AUTOSAR XML (schema 4-2-2)
package /ComponentTypes
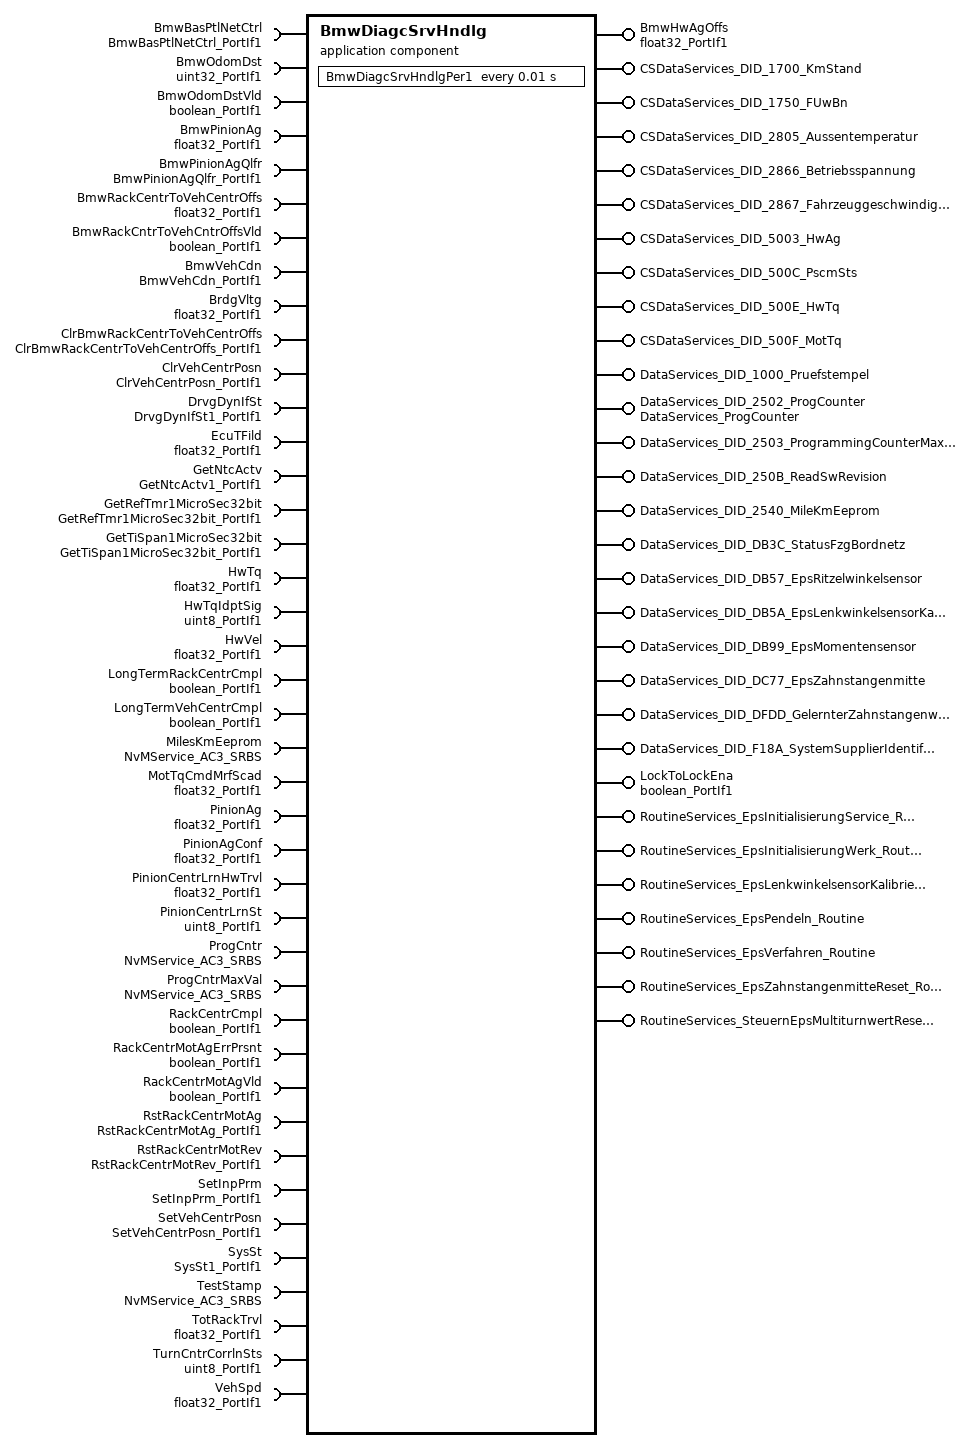
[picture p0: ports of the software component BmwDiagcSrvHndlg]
  application sw component type BmwDiagcSrvHndlg
    30 x provide port:
      BmwHwAgOffs: nonqueued-sender-com-spec{data-element=Val, init-value=0}, provided-interface=float32_PortIf1
      CSDataServices_DID_1700_KmStand: server-com-spec{operation=ReadData, queue-length=1}, provided-interface=CSDataServices_DID_1700_KmStand
      CSDataServices_DID_1750_FUwBn: server-com-spec{operation=ReadData, queue-length=1}, provided-interface=CSDataServices_DID_1750_FUwBn
      CSDataServices_DID_2805_Aussentemperatur: server-com-spec{operation=ReadData, queue-length=1}, provided-interface=CSDataServices_DID_2805_Aussentemperatur
      CSDataServices_DID_2866_Betriebsspannung: server-com-spec{operation=ReadData, queue-length=1}, provided-interface=CSDataServices_DID_2866_Betriebsspannung
      CSDataServices_DID_2867_Fahrzeuggeschwindigkeit: server-com-spec{operation=ReadData, queue-length=1}, provided-interface=CSDataServices_DID_2867_Fahrzeuggeschwindigkeit
      CSDataServices_DID_5003_HwAg: server-com-spec{operation=ReadData, queue-length=1}, provided-interface=CSDataServices_DID_5003_HwAg
      CSDataServices_DID_500C_PscmSts: server-com-spec{operation=ReadData, queue-length=1}, provided-interface=CSDataServices_DID_500C_PscmSts
      CSDataServices_DID_500E_HwTq: server-com-spec{operation=ReadData, queue-length=1}, provided-interface=CSDataServices_DID_500E_HwTq
      CSDataServices_DID_500F_MotTq: server-com-spec{operation=ReadData, queue-length=1}, provided-interface=CSDataServices_DID_500F_MotTq
      DataServices_DID_1000_Pruefstempel: provided-interface=DataServices_DID_1000_Pruefstempel
        provided-com-specs:
          operation=ConditionCheckRead, queue-length=1
          operation=ReadData, queue-length=1
          operation=WriteData, queue-length=1
      DataServices_DID_2502_ProgCounter: server-com-spec{operation=ReadData, queue-length=1}, provided-interface=DataServices_ProgCounter
      DataServices_DID_2503_ProgrammingCounterMaxValue: provided-interface=DataServices_DID_2503_ProgrammingCounterMaxValue
        provided-com-specs:
          operation=ConditionCheckRead, queue-length=1
          operation=ReadData, queue-length=1
          operation=WriteData, queue-length=1
      DataServices_DID_250B_ReadSwRevision: provided-com-specs=[{operation=ConditionCheckRead, queue-length=1}, {operation=ReadData, queue-length=1}], provided-interface=DataServices_DID_250B_ReadSwRevision
      DataServices_DID_2540_MileKmEeprom: provided-com-specs=[{operation=ConditionCheckRead, queue-length=1}, {operation=ReadData, queue-length=1}], provided-interface=DataServices_DID_2540_MileKmEeprom
      DataServices_DID_DB3C_StatusFzgBordnetz: provided-com-specs=[{operation=ConditionCheckRead, queue-length=1}, {operation=ReadData, queue-length=1}], provided-interface=DataServices_DID_DB3C_StatusFzgBordnetz
      DataServices_DID_DB57_EpsRitzelwinkelsensor: provided-com-specs=[{operation=ConditionCheckRead, queue-length=1}, {operation=ReadData, queue-length=1}], provided-interface=DataServices_DID_DB57_EpsRitzelwinkelsensor
      DataServices_DID_DB5A_EpsLenkwinkelsensorKalibrierung: provided-interface=DataServices_DID_DB5A_EpsLenkwinkelsensorKalibrierung
        provided-com-specs:
          operation=ConditionCheckRead, queue-length=1
          operation=ReadData, queue-length=1
          operation=WriteData, queue-length=1
      DataServices_DID_DB99_EpsMomentensensor: provided-com-specs=[{operation=ConditionCheckRead, queue-length=1}, {operation=ReadData, queue-length=1}], provided-interface=DataServices_DID_DB99_EpsMomentensensor
      DataServices_DID_DC77_EpsZahnstangenmitte: provided-com-specs=[{operation=ConditionCheckRead, queue-length=1}, {operation=ReadData, queue-length=1}], provided-interface=DataServices_DID_DC77_EpsZahnstangenmitte
      DataServices_DID_DFDD_GelernterZahnstangenweg: provided-com-specs=[{operation=ConditionCheckRead, queue-length=1}, {operation=ReadData, queue-length=1}], provided-interface=DataServices_DID_DFDD_GelernterZahnstangenweg
      DataServices_DID_F18A_SystemSupplierIdentifier: provided-com-specs=[{operation=ConditionCheckRead, queue-length=1}, {operation=ReadData, queue-length=1}], provided-interface=DataServices_DID_F18A_SystemSupplierIdentifier
      LockToLockEna: nonqueued-sender-com-spec{data-element=Logl, init-value=0}, provided-interface=boolean_PortIf1
      RoutineServices_EpsInitialisierungService_Routine: provided-interface=RoutineServices_EpsInitialisierungService_Routine
        provided-com-specs:
          operation=RequestResults, queue-length=1
          operation=Start, queue-length=1
          operation=Stop, queue-length=1
      RoutineServices_EpsInitialisierungWerk_Routine: provided-interface=RoutineServices_EpsInitialisierungWerk_Routine
        provided-com-specs:
          operation=RequestResults, queue-length=1
          operation=Start, queue-length=1
          operation=Stop, queue-length=1
      RoutineServices_EpsLenkwinkelsensorKalibrierungReset_Routine: server-com-spec{operation=Start, queue-length=1}, provided-interface=RoutineServices_EpsLenkwinkelsensorKalibrierungReset_Routine
      RoutineServices_EpsPendeln_Routine: provided-com-specs=[{operation=RequestResults, queue-length=1}, {operation=Start, queue-length=1}], provided-interface=RoutineServices_EpsPendeln_Routine
      RoutineServices_EpsVerfahren_Routine: provided-com-specs=[{operation=RequestResults, queue-length=1}, {operation=Start, queue-length=1}], provided-interface=RoutineServices_EpsVerfahren_Routine
      RoutineServices_EpsZahnstangenmitteReset_Routine: server-com-spec{operation=Start, queue-length=1}, provided-interface=RoutineServices_EpsZahnstangenmitteReset_Routine
      RoutineServices_SteuernEpsMultiturnwertReset_Routine: server-com-spec{operation=Start, queue-length=1}, provided-interface=RoutineServices_SteuernEpsMultiturnwertReset_Routine
    41 x require port:
      BmwBasPtlNetCtrl: nonqueued-receiver-com-spec{data-element=Val, filter=data-filter-type=ALWAYS, init-value=15}, required-interface=BmwBasPtlNetCtrl_PortIf1
      BmwOdomDst: nonqueued-receiver-com-spec{data-element=Val, filter=data-filter-type=ALWAYS, init-value=0}, required-interface=uint32_PortIf1
      BmwOdomDstVld: nonqueued-receiver-com-spec{data-element=Logl, filter=data-filter-type=ALWAYS, init-value=0}, required-interface=boolean_PortIf1
      BmwPinionAg: nonqueued-receiver-com-spec{data-element=Val, filter=data-filter-type=ALWAYS, init-value=0}, required-interface=float32_PortIf1
      BmwPinionAgQlfr: nonqueued-receiver-com-spec{data-element=Val, filter=data-filter-type=ALWAYS, init-value=14}, required-interface=BmwPinionAgQlfr_PortIf1
      BmwRackCentrToVehCentrOffs: nonqueued-receiver-com-spec{data-element=Val, filter=data-filter-type=ALWAYS, init-value=0}, required-interface=float32_PortIf1
      BmwRackCntrToVehCntrOffsVld: nonqueued-receiver-com-spec{data-element=Logl, filter=data-filter-type=ALWAYS, init-value=0}, required-interface=boolean_PortIf1
      BmwVehCdn: nonqueued-receiver-com-spec{data-element=Val, filter=data-filter-type=ALWAYS, init-value=15}, required-interface=BmwVehCdn_PortIf1
      BrdgVltg: nonqueued-receiver-com-spec{data-element=Val, filter=data-filter-type=ALWAYS, init-value=6}, required-interface=float32_PortIf1
      ClrBmwRackCentrToVehCentrOffs: client-com-spec=Oper, required-interface=ClrBmwRackCentrToVehCentrOffs_PortIf1
      ClrVehCentrPosn: client-com-spec=Oper, required-interface=ClrVehCentrPosn_PortIf1
      DrvgDynIfSt: nonqueued-receiver-com-spec{data-element=Val, filter=data-filter-type=ALWAYS, init-value=128}, required-interface=DrvgDynIfSt1_PortIf1
      EcuTFild: nonqueued-receiver-com-spec{data-element=Val, filter=data-filter-type=ALWAYS, init-value=25}, required-interface=float32_PortIf1
      GetNtcActv: client-com-spec=Oper, required-interface=GetNtcActv1_PortIf1
      GetRefTmr1MicroSec32bit: client-com-spec=Oper, required-interface=GetRefTmr1MicroSec32bit_PortIf1
      GetTiSpan1MicroSec32bit: client-com-spec=Oper, required-interface=GetTiSpan1MicroSec32bit_PortIf1
      HwTq: nonqueued-receiver-com-spec{data-element=Val, filter=data-filter-type=ALWAYS, init-value=0}, required-interface=float32_PortIf1
      HwTqIdptSig: nonqueued-receiver-com-spec{data-element=Val, filter=data-filter-type=ALWAYS, init-value=4}, required-interface=uint8_PortIf1
      HwVel: nonqueued-receiver-com-spec{data-element=Val, filter=data-filter-type=ALWAYS, init-value=0}, required-interface=float32_PortIf1
      LongTermRackCentrCmpl: nonqueued-receiver-com-spec{data-element=Logl, filter=data-filter-type=ALWAYS, init-value=0}, required-interface=boolean_PortIf1
      LongTermVehCentrCmpl: nonqueued-receiver-com-spec{data-element=Logl, filter=data-filter-type=ALWAYS, init-value=0}, required-interface=boolean_PortIf1
      MilesKmEeprom: required-com-specs=[EraseBlock, GetErrorStatus, InvalidateNvBlock, ReadBlock, SetRamBlockStatus, WriteBlock], required-interface=NvMService_AC3_SRBS
      MotTqCmdMrfScad: nonqueued-receiver-com-spec{data-element=Val, filter=data-filter-type=ALWAYS, init-value=0}, required-interface=float32_PortIf1
      PinionAg: nonqueued-receiver-com-spec{data-element=Val, filter=data-filter-type=ALWAYS, init-value=0}, required-interface=float32_PortIf1
      PinionAgConf: nonqueued-receiver-com-spec{data-element=Val, filter=data-filter-type=ALWAYS, init-value=0}, required-interface=float32_PortIf1
      PinionCentrLrnHwTrvl: nonqueued-receiver-com-spec{data-element=Val, filter=data-filter-type=ALWAYS, init-value=0}, required-interface=float32_PortIf1
      PinionCentrLrnSt: nonqueued-receiver-com-spec{data-element=Val, filter=data-filter-type=ALWAYS, init-value=0}, required-interface=uint8_PortIf1
      ProgCntr: required-com-specs=[EraseBlock, GetErrorStatus, InvalidateNvBlock, ReadBlock, SetRamBlockStatus, WriteBlock], required-interface=NvMService_AC3_SRBS
      ProgCntrMaxVal: required-com-specs=[EraseBlock, GetErrorStatus, InvalidateNvBlock, ReadBlock, SetRamBlockStatus, WriteBlock], required-interface=NvMService_AC3_SRBS
      RackCentrCmpl: nonqueued-receiver-com-spec{data-element=Logl, filter=data-filter-type=ALWAYS, init-value=0}, required-interface=boolean_PortIf1
      RackCentrMotAgErrPrsnt: nonqueued-receiver-com-spec{data-element=Logl, filter=data-filter-type=ALWAYS, init-value=0}, required-interface=boolean_PortIf1
      RackCentrMotAgVld: nonqueued-receiver-com-spec{data-element=Logl, filter=data-filter-type=ALWAYS, init-value=0}, required-interface=boolean_PortIf1
      RstRackCentrMotAg: client-com-spec=Oper, required-interface=RstRackCentrMotAg_PortIf1
      RstRackCentrMotRev: client-com-spec=Oper, required-interface=RstRackCentrMotRev_PortIf1
      SetInpPrm: client-com-spec=Oper, required-interface=SetInpPrm_PortIf1
      SetVehCentrPosn: client-com-spec=Oper, required-interface=SetVehCentrPosn_PortIf1
      SysSt: nonqueued-receiver-com-spec{data-element=Val, filter=data-filter-type=ALWAYS, init-value=3}, required-interface=SysSt1_PortIf1
      TestStamp: required-com-specs=[EraseBlock, GetErrorStatus, InvalidateNvBlock, ReadBlock, SetRamBlockStatus, WriteBlock], required-interface=NvMService_AC3_SRBS
      TotRackTrvl: nonqueued-receiver-com-spec{data-element=Val, filter=data-filter-type=ALWAYS, init-value=0}, required-interface=float32_PortIf1
      TurnCntrCorrlnSts: nonqueued-receiver-com-spec{data-element=Val, filter=data-filter-type=ALWAYS, init-value=3}, required-interface=uint8_PortIf1
      VehSpd: nonqueued-receiver-com-spec{data-element=Val, filter=data-filter-type=ALWAYS, init-value=0}, required-interface=float32_PortIf1
    behavior BmwDiagcSrvHndlg_InternalBehavior
      ar-typed-per-instance-memorys:
        20 x data, all with sw-calibration-access=READ-ONLY:
          ActvRid: type=uint16
          HandsONAbort: type=boolean
          HandsONAbortTi: type=uint32
          HandsONStrt: type=boolean
          HandsONStrtTi: type=uint32
          HwAgAbortTi: type=uint32
          HwAgOrHwVelChkRes: type=boolean
          HwVelAbortTi: type=uint32
          LockToLockRountineSts: type=uint8
          LrndPinionCentrHwTrvl: type=float32
          MilesKmEeprom: type=uint32
          OperStEnaWaitTi: type=uint32
          OperStPreStrtChk: type=boolean
          PrevCycleMilesKmEeprom: type=uint32
          ProgCntr: type=uint16
          ProgCntrMaxVal: type=uint16
          RoutineHwPosStrt: type=float32
          TarHwA: type=float32
          TarHwVel: type=float32
          TestStamp: type=Ary1D_u08_3
      46 x operation invoked event:
        OIT_BmwDiagcSrvFHndlgAmbT_Oper_CSDataServices_DID_2805_Aussentemperatur_ReadData: start-on-event=BmwDiagcSrvFHndlgAmbTRead_Oper, operation=CSDataServices_DID_2805_Aussentemperatur.ReadData
        OIT_BmwDiagcSrvFHndlgEpsBaseNwRead_Oper_CSDataServices_DID_1750_FUwBn_ReadData: start-on-event=BmwDiagcSrvFHndlgEpsBaseNwRead_Oper, operation=CSDataServices_DID_1750_FUwBn.ReadData
        OIT_BmwDiagcSrvFHndlgEpsBattVltgRead_Oper_CSDataServices_DID_2866_Betriebsspannung_ReadData: start-on-event=BmwDiagcSrvFHndlgEpsBattVltgRead_Oper, operation=CSDataServices_DID_2866_Betriebsspannung.ReadData
        OIT_BmwDiagcSrvFHndlgEpsFactryIninRes_Oper_RoutineServices_EpsInitialisierungWerk_Routine_RequestResults: start-on-event=BmwDiagcSrvFHndlgEpsFactryIninRes_Oper, operation=RoutineServices_EpsInitialisierungWerk_Routine.RequestResults
        OIT_BmwDiagcSrvFHndlgEpsFactryIninStop_Oper_RoutineServices_EpsInitialisierungWerk_Routine_Stop: start-on-event=BmwDiagcSrvFHndlgEpsFactryIninStop_Oper, operation=RoutineServices_EpsInitialisierungWerk_Routine.Stop
        OIT_BmwDiagcSrvFHndlgEpsFactryIninStrt_Oper_RoutineServices_EpsInitialisierungWerk_Routine_Start: start-on-event=BmwDiagcSrvFHndlgEpsFactryIninStrt_Oper, operation=RoutineServices_EpsInitialisierungWerk_Routine.Start
        OIT_BmwDiagcSrvFHndlgEpsPinionAgSnsrRead_Oper_DataServices_DID_DB57_EpsRitzelwinkelsensor_ReadData: start-on-event=BmwDiagcSrvFHndlgEpsPinionAgSnsrRead_Oper, operation=DataServices_DID_DB57_EpsRitzelwinkelsensor.ReadData
        OIT_BmwDiagcSrvFHndlgEpsPinionAgSnsrReadCdnChk_Oper_DataServices_DID_DB57_EpsRitzelwinkelsensor_ConditionCheckRead: start-on-event=BmwDiagcSrvFHndlgEpsPinionAgSnsrReadCdnChk_Oper, operation=DataServices_DID_DB57_EpsRitzelwinkelsensor.ConditionCheckRead
        OIT_BmwDiagcSrvFHndlgEpsProgCntrMaxValWrite_Oper_DataServices_DID_2503_ProgrammingCounterMaxValue_WriteData: start-on-event=BmwDiagcSrvFHndlgEpsProgCntrMaxValWrite_Oper, operation=DataServices_DID_2503_ProgrammingCounterMaxValue.WriteData
        OIT_BmwDiagcSrvFHndlgEpsSteerAgSnsrCalRead_Oper_DataServices_DID_DB5A_EpsLenkwinkelsensorKalibrierung_ReadData: start-on-event=BmwDiagcSrvFHndlgEpsSteerAgSnsrCalRead_Oper, operation=DataServices_DID_DB5A_EpsLenkwinkelsensorKalibrierung.ReadData
        OIT_BmwDiagcSrvFHndlgEpsSteerAgSnsrCalReadCdnChk_Oper_DataServices_DID_DB5A_EpsLenkwinkelsensorKalibrierung_ConditionCheckRead: start-on-event=BmwDiagcSrvFHndlgEpsSteerAgSnsrCalReadCdnChk_Oper, operation=DataServices_DID_DB5A_EpsLenkwinkelsensorKalibrierung.ConditionCheckRead
        OIT_BmwDiagcSrvFHndlgEpsSteerAgSnsrCalWrite_Oper_DataServices_DID_DB5A_EpsLenkwinkelsensorKalibrierung_WriteData: start-on-event=BmwDiagcSrvFHndlgEpsSteerAgSnsrCalWrite_Oper, operation=DataServices_DID_DB5A_EpsLenkwinkelsensorKalibrierung.WriteData
        OIT_BmwDiagcSrvFHndlgEpsTestStampRead_Oper_DataServices_DID_1000_Pruefstempel_ReadData: start-on-event=BmwDiagcSrvFHndlgEpsTestStampRead_Oper, operation=DataServices_DID_1000_Pruefstempel.ReadData
        OIT_BmwDiagcSrvFHndlgEpsTestStampReadCdnChk_Oper_DataServices_DID_1000_Pruefstempel_ConditionCheckRead: start-on-event=BmwDiagcSrvFHndlgEpsTestStampReadCdnChk_Oper, operation=DataServices_DID_1000_Pruefstempel.ConditionCheckRead
        OIT_BmwDiagcSrvFHndlgEpsTestStampWrite_Oper_DataServices_DID_1000_Pruefstempel_WriteData: start-on-event=BmwDiagcSrvFHndlgEpsTestStampWrite_Oper, operation=DataServices_DID_1000_Pruefstempel.WriteData
        OIT_BmwDiagcSrvFHndlgHwAgRead_Oper_CSDataServices_DID_5003_HwAg_ReadData: start-on-event=BmwDiagcSrvFHndlgHwAgRead_Oper, operation=CSDataServices_DID_5003_HwAg.ReadData
        OIT_BmwDiagcSrvFHndlgHwTqRead_Oper_CSDataServices_DID_500E_HwTq_ReadData: start-on-event=BmwDiagcSrvFHndlgHwTqRead_Oper, operation=CSDataServices_DID_500E_HwTq.ReadData
        OIT_BmwDiagcSrvFHndlgMileKmEepromRead_Oper_DataServices_DID_2540_MileKmEeprom_ReadData: start-on-event=BmwDiagcSrvFHndlgMileKmEepromRead_Oper, operation=DataServices_DID_2540_MileKmEeprom.ReadData
        OIT_BmwDiagcSrvFHndlgMileKmEepromReadCdnChk_Oper_DataServices_DID_2540_MileKmEeprom_ConditionCheckRead: start-on-event=BmwDiagcSrvFHndlgMileKmEepromReadCdnChk_Oper, operation=DataServices_DID_2540_MileKmEeprom.ConditionCheckRead
        OIT_BmwDiagcSrvFHndlgMotTqRead_Oper_CSDataServices_DID_500F_MotTq_ReadData: start-on-event=BmwDiagcSrvFHndlgMotTqRead_Oper, operation=CSDataServices_DID_500F_MotTq.ReadData
        OIT_BmwDiagcSrvFHndlgProgmCntrMaxValRead_Oper_DataServices_DID_2503_ProgrammingCounterMaxValue_ReadData: start-on-event=BmwDiagcSrvFHndlgProgmCntrMaxValRead_Oper, operation=DataServices_DID_2503_ProgrammingCounterMaxValue.ReadData
        OIT_BmwDiagcSrvFHndlgProgmCntrMaxValReadCdnChk_Oper_DataServices_DID_2503_ProgrammingCounterMaxValue_ConditionCheckRead: start-on-event=BmwDiagcSrvFHndlgProgmCntrMaxValReadCdnChk_Oper, operation=DataServices_DID_2503_ProgrammingCounterMaxValue.ConditionCheckRead
        OIT_BmwDiagcSrvFHndlgProgmCntrRead_Oper_DataServices_DID_2502_ProgCounter_ReadData: start-on-event=BmwDiagcSrvFHndlgProgmCntrRead_Oper, operation=DataServices_DID_2502_ProgCounter.ReadData
        OIT_BmwDiagcSrvFHndlgPscmStsRead_Oper_CSDataServices_DID_500C_PscmSts_ReadData: start-on-event=BmwDiagcSrvFHndlgPscmStsRead_Oper, operation=CSDataServices_DID_500C_PscmSts.ReadData
        OIT_BmwDiagcSrvFHndlgReadSwRevision_Oper_DataServices_DID_250B_ReadSwRevision_ReadData: start-on-event=BmwDiagcSrvFHndlgReadSwRevision_Oper, operation=DataServices_DID_250B_ReadSwRevision.ReadData
        OIT_BmwDiagcSrvFHndlgReadSwRevisionCdnChk_Oper_DataServices_DID_250B_ReadSwRevision_ConditionCheckRead: start-on-event=BmwDiagcSrvFHndlgReadSwRevisionCdnChk_Oper, operation=DataServices_DID_250B_ReadSwRevision.ConditionCheckRead
        OIT_BmwDiagcSrvFHndlgStordRackTrvlAndCentrDataRead_Oper_DataServices_DID_DFDD_GelernterZahnstangenweg_ReadData: start-on-event=BmwDiagcSrvFHndlgStordRackTrvlAndCentrDataRead_Oper, operation=DataServices_DID_DFDD_GelernterZahnstangenweg.ReadData
        OIT_BmwDiagcSrvFHndlgStordRackTrvlAndCentrDataReadCdnChk_Oper_DataServices_DID_DFDD_GelernterZahnstangenweg_ConditionCheckRead: start-on-event=BmwDiagcSrvFHndlgStordRackTrvlAndCentrDataReadCdnChk_Oper, operation=DataServices_DID_DFDD_GelernterZahnstangenweg.ConditionCheckRead
        OIT_BmwDiagcSrvFHndlgSysSupplierIdentifieCdnChk_Oper_DataServices_DID_F18A_SystemSupplierIdentifier_ConditionCheckRead: start-on-event=BmwDiagcSrvFHndlgSysSupplierIdentifierCdnChk_Oper, operation=DataServices_DID_F18A_SystemSupplierIdentifier.ConditionCheckRead
        OIT_BmwDiagcSrvFHndlgSysSupplierIdentifierRead_Oper_DataServices_DID_F18A_SystemSupplierIdentifier_ReadData: start-on-event=BmwDiagcSrvFHndlgSysSupplierIdentifierRead_Oper, operation=DataServices_DID_F18A_SystemSupplierIdentifier.ReadData
        OIT_BmwDiagcSrvFHndlgVehSpdRead_Oper_CSDataServices_DID_2867_Fahrzeuggeschwindigkeit_ReadData: start-on-event=BmwDiagcSrvFHndlgVehSpdRead_Oper, operation=CSDataServices_DID_2867_Fahrzeuggeschwindigkeit.ReadData
        OIT_BmwDiagcSrvFHndlMileageRead_Oper_CSDataServices_DID_1700_KmStand_ReadData: start-on-event=BmwDiagcSrvFHndlMileageRead_Oper, operation=CSDataServices_DID_1700_KmStand.ReadData
        OIT_BmwDiagcSrvHndlgEpsCommuteRes_Oper_RoutineServices_EpsPendeln_Routine_RequestResults: start-on-event=BmwDiagcSrvHndlgEpsCommuteRes_Oper, operation=RoutineServices_EpsPendeln_Routine.RequestResults
        OIT_BmwDiagcSrvHndlgEpsCommuteStrt_Oper_RoutineServices_EpsPendeln_Routine_Start: start-on-event=BmwDiagcSrvHndlgEpsCommuteStrt_Oper, operation=RoutineServices_EpsPendeln_Routine.Start
        OIT_BmwDiagcSrvHndlgEpsIninSrvRes_Oper_RoutineServices_EpsInitialisierungService_Routine_RequestResults: start-on-event=BmwDiagcSrvHndlgEpsIninSrvRes_Oper, operation=RoutineServices_EpsInitialisierungService_Routine.RequestResults
        OIT_BmwDiagcSrvHndlgEpsIninSrvStop_Oper_RoutineServices_EpsInitialisierungService_Routine_Stop: start-on-event=BmwDiagcSrvHndlgEpsIninSrvStop_Oper, operation=RoutineServices_EpsInitialisierungService_Routine.Stop
        OIT_BmwDiagcSrvHndlgEpsIninSrvStrt_Oper_RoutineServices_EpsInitialisierungService_Routine_Start: start-on-event=BmwDiagcSrvHndlgEpsIninSrvStrt_Oper, operation=RoutineServices_EpsInitialisierungService_Routine.Start
        OIT_BmwDiagcSrvHndlgEpsProcRes_Oper_RoutineServices_EpsVerfahren_Routine_RequestResults: start-on-event=BmwDiagcSrvHndlgEpsProcRes_Oper, operation=RoutineServices_EpsVerfahren_Routine.RequestResults
        OIT_BmwDiagcSrvHndlgEpsProcStrt_Oper_RoutineServices_EpsVerfahren_Routine_Start: start-on-event=BmwDiagcSrvHndlgEpsProcStrt_Oper, operation=RoutineServices_EpsVerfahren_Routine.Start
        OIT_BmwDiagcSrvHndlgEpsPtlRackCentrRstStrt_Oper_RoutineServices_SteuernEpsMultiturnwertReset_Routine_Start: start-on-event=BmwDiagcSrvHndlgEpsPtlRackCentrRstStrt_Oper, operation=RoutineServices_SteuernEpsMultiturnwertReset_Routine.Start
        OIT_BmwDiagcSrvHndlgEpsRackCentrMotAgStsRead_Oper_DataServices_DID_DC77_EpsZahnstangenmitte_ReadData: start-on-event=BmwDiagcSrvHndlgEpsRackCentrMotAgStsRead_Oper, operation=DataServices_DID_DC77_EpsZahnstangenmitte.ReadData
        OIT_BmwDiagcSrvHndlgEpsRackCentrMotAgStsReadCdnChk_Oper_DataServices_DID_DC77_EpsZahnstangenmitte_ConditionCheckRead: start-on-event=BmwDiagcSrvHndlgEpsRackCentrMotAgStsReadCdnChk_Oper, operation=DataServices_DID_DC77_EpsZahnstangenmitte.ConditionCheckRead
        OIT_BmwDiagcSrvHndlgEpsRackCentrRstStrt_Oper_RoutineServices_EpsZahnstangenmitteReset_Routine_Start: start-on-event=BmwDiagcSrvHndlgEpsRackCentrRstStrt_Oper, operation=RoutineServices_EpsZahnstangenmitteReset_Routine.Start
        OIT_BmwDiagcSrvHndlgEpsSteerAgSnsrCalRstStrt_Oper_RoutineServices_EpsLenkwinkelsensorKalibrierungReset_Routine_Start: start-on-event=BmwDiagcSrvHndlgEpsSteerAgSnsrCalRstStrt_Oper, operation=RoutineServices_EpsLenkwinkelsensorKalibrierungReset_Routine.Start
        OIT_BmwDiagcSrvHndlgEpsTqSensrRead_Oper_DataServices_DID_DB99_EpsMomentensensor_ReadData: start-on-event=BmwDiagcSrvHndlgEpsTqSensrRead_Oper, operation=DataServices_DID_DB99_EpsMomentensensor.ReadData
        OIT_BmwDiagcSrvHndlgEpsTqSensrReadCdnChk_Oper_DataServices_DID_DB99_EpsMomentensensor_ConditionCheckRead: start-on-event=BmwDiagcSrvHndlgEpsTqSensrReadCdnChk_Oper, operation=DataServices_DID_DB99_EpsMomentensensor.ConditionCheckRead
      init event BmwDiagcSrvHndlig_InitEvent: start-on-event=BmwDiagcSrvHndlgInit1
      timing event TMT_BmwDiagcSrvHndlgPer1: start-on-event=BmwDiagcSrvHndlgPer1, period=0.01
      operation invoked event OIT_BmwDiagcSrvHndlgStatusFzgBordnetzRead_Oper_DataServices_DID_DB3C_StatusFzgBordnetz_ReadData: start-on-event=BmwDiagcSrvHndlgStatusFzgBordnetzRead_Oper, operation=DataServices_DID_DB3C_StatusFzgBordnetz.ReadData
      operation invoked event OIT_BmwDiagcSrvHndlgStatusFzgBordnetzReadCdnChk_Oper_DataServices_DID_DB3C_StatusFzgBordnetz_ConditionCheckRead: start-on-event=BmwDiagcSrvHndlgStatusFzgBordnetzReadCdnChk_Oper, operation=DataServices_DID_DB3C_StatusFzgBordnetz.ConditionCheckRead
      per-instance-parameters:
        parameter data prototype ProgCntrMaxValDft: sw-calibration-access=READ-WRITE, type=uint16, init-value=1000
      port-api-options:
        enable-take-address=false, error-handling=NO-TRANSFORMER-ERROR-HANDLING, indirect-api=false, port=BmwBasPtlNetCtrl
        enable-take-address=false, error-handling=NO-TRANSFORMER-ERROR-HANDLING, indirect-api=false, port=BmwHwAgOffs
        enable-take-address=false, error-handling=NO-TRANSFORMER-ERROR-HANDLING, indirect-api=false, port=BmwOdomDst
        enable-take-address=false, error-handling=NO-TRANSFORMER-ERROR-HANDLING, indirect-api=false, port=BmwOdomDstVld
        enable-take-address=false, error-handling=NO-TRANSFORMER-ERROR-HANDLING, indirect-api=false, port=BmwPinionAg
        enable-take-address=false, error-handling=NO-TRANSFORMER-ERROR-HANDLING, indirect-api=false, port=BmwPinionAgQlfr
        enable-take-address=false, error-handling=NO-TRANSFORMER-ERROR-HANDLING, indirect-api=false, port=BmwRackCentrToVehCentrOffs
        enable-take-address=false, error-handling=NO-TRANSFORMER-ERROR-HANDLING, indirect-api=false, port=BmwRackCntrToVehCntrOffsVld
        enable-take-address=false, error-handling=NO-TRANSFORMER-ERROR-HANDLING, indirect-api=false, port=BmwVehCdn
        enable-take-address=false, error-handling=NO-TRANSFORMER-ERROR-HANDLING, indirect-api=false, port=BrdgVltg
        enable-take-address=false, error-handling=NO-TRANSFORMER-ERROR-HANDLING, indirect-api=false, port=ClrBmwRackCentrToVehCentrOffs
        enable-take-address=false, error-handling=NO-TRANSFORMER-ERROR-HANDLING, indirect-api=false, port=ClrVehCentrPosn
        enable-take-address=false, error-handling=NO-TRANSFORMER-ERROR-HANDLING, indirect-api=false, port=CSDataServices_DID_1700_KmStand
        enable-take-address=false, error-handling=NO-TRANSFORMER-ERROR-HANDLING, indirect-api=false, port=CSDataServices_DID_1750_FUwBn
        enable-take-address=false, error-handling=NO-TRANSFORMER-ERROR-HANDLING, indirect-api=false, port=CSDataServices_DID_2805_Aussentemperatur
        enable-take-address=false, error-handling=NO-TRANSFORMER-ERROR-HANDLING, indirect-api=false, port=CSDataServices_DID_2866_Betriebsspannung
        enable-take-address=false, error-handling=NO-TRANSFORMER-ERROR-HANDLING, indirect-api=false, port=CSDataServices_DID_2867_Fahrzeuggeschwindigkeit
        enable-take-address=false, error-handling=NO-TRANSFORMER-ERROR-HANDLING, indirect-api=false, port=CSDataServices_DID_5003_HwAg
        enable-take-address=false, error-handling=NO-TRANSFORMER-ERROR-HANDLING, indirect-api=false, port=CSDataServices_DID_500C_PscmSts
        enable-take-address=false, error-handling=NO-TRANSFORMER-ERROR-HANDLING, indirect-api=false, port=CSDataServices_DID_500E_HwTq
        enable-take-address=false, error-handling=NO-TRANSFORMER-ERROR-HANDLING, indirect-api=false, port=CSDataServices_DID_500F_MotTq
        enable-take-address=false, error-handling=NO-TRANSFORMER-ERROR-HANDLING, indirect-api=false, port=DataServices_DID_1000_Pruefstempel
        enable-take-address=false, error-handling=NO-TRANSFORMER-ERROR-HANDLING, indirect-api=false, port=DataServices_DID_2502_ProgCounter
        enable-take-address=false, error-handling=NO-TRANSFORMER-ERROR-HANDLING, indirect-api=false, port=DataServices_DID_2503_ProgrammingCounterMaxValue
        enable-take-address=false, error-handling=NO-TRANSFORMER-ERROR-HANDLING, indirect-api=false, port=DataServices_DID_250B_ReadSwRevision
        enable-take-address=false, error-handling=NO-TRANSFORMER-ERROR-HANDLING, indirect-api=false, port=DataServices_DID_2540_MileKmEeprom
        enable-take-address=false, error-handling=NO-TRANSFORMER-ERROR-HANDLING, indirect-api=false, port=DataServices_DID_DB3C_StatusFzgBordnetz
        enable-take-address=false, error-handling=NO-TRANSFORMER-ERROR-HANDLING, indirect-api=false, port=DataServices_DID_DB57_EpsRitzelwinkelsensor
        enable-take-address=false, error-handling=NO-TRANSFORMER-ERROR-HANDLING, indirect-api=false, port=DataServices_DID_DB5A_EpsLenkwinkelsensorKalibrierung
        enable-take-address=false, error-handling=NO-TRANSFORMER-ERROR-HANDLING, indirect-api=false, port=DataServices_DID_DB99_EpsMomentensensor
        enable-take-address=false, error-handling=NO-TRANSFORMER-ERROR-HANDLING, indirect-api=false, port=DataServices_DID_DC77_EpsZahnstangenmitte
        enable-take-address=false, error-handling=NO-TRANSFORMER-ERROR-HANDLING, indirect-api=false, port=DataServices_DID_DFDD_GelernterZahnstangenweg
        enable-take-address=false, error-handling=NO-TRANSFORMER-ERROR-HANDLING, indirect-api=false, port=DataServices_DID_F18A_SystemSupplierIdentifier
        enable-take-address=false, error-handling=NO-TRANSFORMER-ERROR-HANDLING, indirect-api=false, port=DrvgDynIfSt
        enable-take-address=false, error-handling=NO-TRANSFORMER-ERROR-HANDLING, indirect-api=false, port=EcuTFild
        enable-take-address=false, error-handling=NO-TRANSFORMER-ERROR-HANDLING, indirect-api=false, port=GetNtcActv
        enable-take-address=false, error-handling=NO-TRANSFORMER-ERROR-HANDLING, indirect-api=false, port=GetRefTmr1MicroSec32bit
        enable-take-address=false, error-handling=NO-TRANSFORMER-ERROR-HANDLING, indirect-api=false, port=GetTiSpan1MicroSec32bit
        enable-take-address=false, error-handling=NO-TRANSFORMER-ERROR-HANDLING, indirect-api=false, port=HwTq
        enable-take-address=false, error-handling=NO-TRANSFORMER-ERROR-HANDLING, indirect-api=false, port=HwTqIdptSig
        enable-take-address=false, error-handling=NO-TRANSFORMER-ERROR-HANDLING, indirect-api=false, port=HwVel
        enable-take-address=false, error-handling=NO-TRANSFORMER-ERROR-HANDLING, indirect-api=false, port=LockToLockEna
        enable-take-address=false, error-handling=NO-TRANSFORMER-ERROR-HANDLING, indirect-api=false, port=LongTermRackCentrCmpl
        enable-take-address=false, error-handling=NO-TRANSFORMER-ERROR-HANDLING, indirect-api=false, port=LongTermVehCentrCmpl
        enable-take-address=false, error-handling=NO-TRANSFORMER-ERROR-HANDLING, indirect-api=false, port=MilesKmEeprom
        enable-take-address=false, error-handling=NO-TRANSFORMER-ERROR-HANDLING, indirect-api=false, port=MotTqCmdMrfScad
        enable-take-address=false, error-handling=NO-TRANSFORMER-ERROR-HANDLING, indirect-api=false, port=PinionAg
        enable-take-address=false, error-handling=NO-TRANSFORMER-ERROR-HANDLING, indirect-api=false, port=PinionAgConf
        enable-take-address=false, error-handling=NO-TRANSFORMER-ERROR-HANDLING, indirect-api=false, port=PinionCentrLrnHwTrvl
        enable-take-address=false, error-handling=NO-TRANSFORMER-ERROR-HANDLING, indirect-api=false, port=PinionCentrLrnSt
        enable-take-address=false, error-handling=NO-TRANSFORMER-ERROR-HANDLING, indirect-api=false, port=ProgCntr
        enable-take-address=false, error-handling=NO-TRANSFORMER-ERROR-HANDLING, indirect-api=false, port=ProgCntrMaxVal
        enable-take-address=false, error-handling=NO-TRANSFORMER-ERROR-HANDLING, indirect-api=false, port=RackCentrCmpl
        enable-take-address=false, error-handling=NO-TRANSFORMER-ERROR-HANDLING, indirect-api=false, port=RackCentrMotAgErrPrsnt
        enable-take-address=false, error-handling=NO-TRANSFORMER-ERROR-HANDLING, indirect-api=false, port=RackCentrMotAgVld
        enable-take-address=false, error-handling=NO-TRANSFORMER-ERROR-HANDLING, indirect-api=false, port=RoutineServices_EpsInitialisierungService_Routine
        enable-take-address=false, error-handling=NO-TRANSFORMER-ERROR-HANDLING, indirect-api=false, port=RoutineServices_EpsInitialisierungWerk_Routine
        enable-take-address=false, error-handling=NO-TRANSFORMER-ERROR-HANDLING, indirect-api=false, port=RoutineServices_EpsLenkwinkelsensorKalibrierungReset_Routine
        enable-take-address=false, error-handling=NO-TRANSFORMER-ERROR-HANDLING, indirect-api=false, port=RoutineServices_EpsPendeln_Routine
        enable-take-address=false, error-handling=NO-TRANSFORMER-ERROR-HANDLING, indirect-api=false, port=RoutineServices_EpsVerfahren_Routine
        enable-take-address=false, error-handling=NO-TRANSFORMER-ERROR-HANDLING, indirect-api=false, port=RoutineServices_EpsZahnstangenmitteReset_Routine
        enable-take-address=false, error-handling=NO-TRANSFORMER-ERROR-HANDLING, indirect-api=false, port=RoutineServices_SteuernEpsMultiturnwertReset_Routine
        enable-take-address=false, error-handling=NO-TRANSFORMER-ERROR-HANDLING, indirect-api=false, port=RstRackCentrMotAg
        enable-take-address=false, error-handling=NO-TRANSFORMER-ERROR-HANDLING, indirect-api=false, port=RstRackCentrMotRev
        enable-take-address=false, error-handling=NO-TRANSFORMER-ERROR-HANDLING, indirect-api=false, port=SetInpPrm
        enable-take-address=false, error-handling=NO-TRANSFORMER-ERROR-HANDLING, indirect-api=false, port=SetVehCentrPosn
        enable-take-address=false, error-handling=NO-TRANSFORMER-ERROR-HANDLING, indirect-api=false, port=SysSt
        enable-take-address=false, error-handling=NO-TRANSFORMER-ERROR-HANDLING, indirect-api=false, port=TestStamp
        enable-take-address=false, error-handling=NO-TRANSFORMER-ERROR-HANDLING, indirect-api=false, port=TotRackTrvl
        enable-take-address=false, error-handling=NO-TRANSFORMER-ERROR-HANDLING, indirect-api=false, port=TurnCntrCorrlnSts
        enable-take-address=false, error-handling=NO-TRANSFORMER-ERROR-HANDLING, indirect-api=false, port=VehSpd
      50 x runnable:
        BmwDiagcSrvFHndlgAmbTRead_Oper
          data-receive-point-by-arguments:
            access REC_EcuTFild_Val: accessed-variable=EcuTFild.Val
        BmwDiagcSrvFHndlgEpsBaseNwRead_Oper
          data-receive-point-by-arguments:
            access REC_BmwBasPtlNetCtrl_Val: accessed-variable=BmwBasPtlNetCtrl.Val
            access REC_BmwVehCdn_Val: accessed-variable=BmwVehCdn.Val
        BmwDiagcSrvFHndlgEpsBattVltgRead_Oper
          data-receive-point-by-arguments:
            access REC_BrdgVltg_Val: accessed-variable=BrdgVltg.Val
        BmwDiagcSrvFHndlgEpsFactryIninRes_Oper
        BmwDiagcSrvFHndlgEpsFactryIninStop_Oper
          data-send-points:
            access SEND_LockToLockEna_Logl: accessed-variable=LockToLockEna.Logl
        BmwDiagcSrvFHndlgEpsFactryIninStrt_Oper
          data-receive-point-by-arguments:
            6 x access:
              REC_HwTq_Val: accessed-variable=HwTq.Val
              REC_HwVel_Val: accessed-variable=HwVel.Val
              REC_LongTermRackCentrCmpl_Logl: accessed-variable=LongTermRackCentrCmpl.Logl
              REC_PinionAgConf_Val: accessed-variable=PinionAgConf.Val
              REC_SysSt_Val: accessed-variable=SysSt.Val
              REC_VehSpd_Val: accessed-variable=VehSpd.Val
          data-send-points:
            access SEND_LockToLockEna_Logl: accessed-variable=LockToLockEna.Logl
          sync call SC_GetRefTmr1MicroSec32bit_PortIf1_Oper: operation=GetRefTmr1MicroSec32bit.Oper, timeout=0
          sync call SC_GetTiSpan1MicroSec32bit_PortIf1_Oper: operation=GetTiSpan1MicroSec32bit.Oper, timeout=0
          sync call SC_SetInpPrm_Oper: operation=SetInpPrm.Oper, timeout=0
        BmwDiagcSrvFHndlgEpsPinionAgSnsrRead_Oper
          data-receive-point-by-arguments:
            5 x access:
              REC_HwVel_Val: accessed-variable=HwVel.Val
              REC_LongTermRackCentrCmpl_Logl: accessed-variable=LongTermRackCentrCmpl.Logl
              REC_LongTermVehCentrCmpl_Logl: accessed-variable=LongTermVehCentrCmpl.Logl
              REC_PinionAg_Val: accessed-variable=PinionAg.Val
              REC_TurnCntrCorrlnSts_Val: accessed-variable=TurnCntrCorrlnSts.Val
        BmwDiagcSrvFHndlgEpsPinionAgSnsrReadCdnChk_Oper
        BmwDiagcSrvFHndlgEpsProgCntrMaxValWrite_Oper
          sync call SC_NvmProgCntrMaxVal_SetRamBlockStatus: operation=ProgCntrMaxVal.SetRamBlockStatus, timeout=0
        BmwDiagcSrvFHndlgEpsSteerAgSnsrCalRead_Oper
          data-receive-point-by-arguments:
            access REC_BmwRackCentrToVehCentrOffs_Val: accessed-variable=BmwRackCentrToVehCentrOffs.Val
            access REC_BmwRackCntrToVehCntrOffsVld_Logl: accessed-variable=BmwRackCntrToVehCntrOffsVld.Logl
        BmwDiagcSrvFHndlgEpsSteerAgSnsrCalReadCdnChk_Oper
        BmwDiagcSrvFHndlgEpsSteerAgSnsrCalWrite_Oper
          data-send-points:
            access SEND_BmwHwAgOffs_Val: accessed-variable=BmwHwAgOffs.Val
          sync call SC_SetVehCentrPosn_Oper: operation=SetVehCentrPosn.Oper, timeout=0
        BmwDiagcSrvFHndlgEpsTestStampRead_Oper
          sync call SC_TestStamp_GetErrorStatus: operation=TestStamp.GetErrorStatus, timeout=0
        BmwDiagcSrvFHndlgEpsTestStampReadCdnChk_Oper
        BmwDiagcSrvFHndlgEpsTestStampWrite_Oper
          sync call SC_TestStamp_SetRamBlockStatus: operation=TestStamp.SetRamBlockStatus, timeout=0
        BmwDiagcSrvFHndlgHwAgRead_Oper
          data-receive-point-by-arguments:
            access REC_BmwPinionAg_Val: accessed-variable=BmwPinionAg.Val
        BmwDiagcSrvFHndlgHwTqRead_Oper
          data-receive-point-by-arguments:
            access REC_HwTq_Val: accessed-variable=HwTq.Val
        BmwDiagcSrvFHndlgMileKmEepromRead_Oper
          data-receive-point-by-arguments:
            access REC_BmwOdomDst_Val: accessed-variable=BmwOdomDst.Val
        BmwDiagcSrvFHndlgMileKmEepromReadCdnChk_Oper
        BmwDiagcSrvFHndlgMotTqRead_Oper
          data-receive-point-by-arguments:
            access REC_MotTqCmdMrfScad_Val: accessed-variable=MotTqCmdMrfScad.Val
        BmwDiagcSrvFHndlgProgmCntrMaxValRead_Oper
        BmwDiagcSrvFHndlgProgmCntrMaxValReadCdnChk_Oper
        BmwDiagcSrvFHndlgProgmCntrRead_Oper
          sync call SC_NvmProgCntr_GetErrorStatus: operation=ProgCntr.GetErrorStatus, timeout=0
        BmwDiagcSrvFHndlgPscmStsRead_Oper
          data-receive-point-by-arguments:
            access REC_DrvgDynIfSt_Val: accessed-variable=DrvgDynIfSt.Val
            access REC_PinionAgConf_Val: accessed-variable=PinionAgConf.Val
            access REC_SysSt_Val: accessed-variable=SysSt.Val
          sync call SC_GetNtcActv_Oper: operation=GetNtcActv.Oper, timeout=0
        BmwDiagcSrvFHndlgReadSwRevision_Oper
        BmwDiagcSrvFHndlgReadSwRevisionCdnChk_Oper
        BmwDiagcSrvFHndlgStordRackTrvlAndCentrDataRead_Oper
          data-receive-point-by-arguments:
            access REC_RackCentrMotAgErrPrsnt_Logl: accessed-variable=RackCentrMotAgErrPrsnt.Logl
            access REC_TotRackTrvl_Val: accessed-variable=TotRackTrvl.Val
        BmwDiagcSrvFHndlgStordRackTrvlAndCentrDataReadCdnChk_Oper
        BmwDiagcSrvFHndlgSysSupplierIdentifierCdnChk_Oper
        BmwDiagcSrvFHndlgSysSupplierIdentifierRead_Oper
        BmwDiagcSrvFHndlgVehSpdRead_Oper
          data-receive-point-by-arguments:
            access REC_VehSpd_Val: accessed-variable=VehSpd.Val
        BmwDiagcSrvFHndlMileageRead_Oper
          data-receive-point-by-arguments:
            access REC_BmwOdomDst_Val: accessed-variable=BmwOdomDst.Val
            access REC_BmwOdomDstVld_Logl: accessed-variable=BmwOdomDstVld.Logl
        BmwDiagcSrvHndlgEpsCommuteRes_Oper
        BmwDiagcSrvHndlgEpsCommuteStrt_Oper
        BmwDiagcSrvHndlgEpsIninSrvRes_Oper
        BmwDiagcSrvHndlgEpsIninSrvStop_Oper
        BmwDiagcSrvHndlgEpsIninSrvStrt_Oper
        BmwDiagcSrvHndlgEpsProcRes_Oper
        BmwDiagcSrvHndlgEpsProcStrt_Oper
        BmwDiagcSrvHndlgEpsPtlRackCentrRstStrt_Oper
          data-receive-point-by-arguments:
            access REC_VehSpd_Val: accessed-variable=VehSpd.Val
          sync call SC_ClrBmwRackCentrToVehCentrOffs_Oper: operation=ClrBmwRackCentrToVehCentrOffs.Oper, timeout=0
          sync call SC_ClrVehCentrPosn_Oper: operation=ClrVehCentrPosn.Oper, timeout=0
          sync call SC_RstRackCentrMotRev_Oper: operation=RstRackCentrMotRev.Oper, timeout=0
        BmwDiagcSrvHndlgEpsRackCentrMotAgStsRead_Oper
          data-receive-point-by-arguments:
            4 x access:
              REC_LongTermRackCentrCmpl_Logl: accessed-variable=LongTermRackCentrCmpl.Logl
              REC_RackCentrCmpl_Logl: accessed-variable=RackCentrCmpl.Logl
              REC_RackCentrMotAgErrPrsnt_Logl: accessed-variable=RackCentrMotAgErrPrsnt.Logl
              REC_RackCentrMotAgVld_Logl: accessed-variable=RackCentrMotAgVld.Logl
        BmwDiagcSrvHndlgEpsRackCentrMotAgStsReadCdnChk_Oper
        BmwDiagcSrvHndlgEpsRackCentrRstStrt_Oper
          data-receive-point-by-arguments:
            access REC_BmwPinionAgQlfr_Val: accessed-variable=BmwPinionAgQlfr.Val
            access REC_VehSpd_Val: accessed-variable=VehSpd.Val
          sync call SC_ClrBmwRackCentrToVehCentrOffs_Oper: operation=ClrBmwRackCentrToVehCentrOffs.Oper, timeout=0
          sync call SC_RstRackCentrMotAg_Oper: operation=RstRackCentrMotAg.Oper, timeout=0
          sync call SC_RstRackCentrMotRev_Oper: operation=RstRackCentrMotRev.Oper, timeout=0
        BmwDiagcSrvHndlgEpsSteerAgSnsrCalRstStrt_Oper
          data-receive-point-by-arguments:
            access REC_BmwPinionAgQlfr_Val: accessed-variable=BmwPinionAgQlfr.Val
            access REC_VehSpd_Val: accessed-variable=VehSpd.Val
          sync call SC_ClrBmwRackCentrToVehCentrOffs_Oper: operation=ClrBmwRackCentrToVehCentrOffs.Oper, timeout=0
          sync call SC_ClrVehCentrPosn_Oper: operation=ClrVehCentrPosn.Oper, timeout=0
          sync call SC_RstRackCentrMotRev_Oper: operation=RstRackCentrMotRev.Oper, timeout=0
        BmwDiagcSrvHndlgEpsTqSensrRead_Oper
          data-receive-point-by-arguments:
            access REC_HwTq_Val: accessed-variable=HwTq.Val
            access REC_HwTqIdptSig_Val: accessed-variable=HwTqIdptSig.Val
        BmwDiagcSrvHndlgEpsTqSensrReadCdnChk_Oper
        BmwDiagcSrvHndlgInit1
        BmwDiagcSrvHndlgPer1
          data-receive-point-by-arguments:
            6 x access:
              REC_BmwOdomDst_Val: accessed-variable=BmwOdomDst.Val
              REC_HwTq_Val: accessed-variable=HwTq.Val
              REC_HwVel_Val: accessed-variable=HwVel.Val
              REC_PinionAg_Val: accessed-variable=PinionAg.Val
              REC_PinionCentrLrnHwTrvl_Val: accessed-variable=PinionCentrLrnHwTrvl.Val
              REC_PinionCentrLrnSt_Val: accessed-variable=PinionCentrLrnSt.Val
          data-send-points:
            access SEND_LockToLockEna_Logl: accessed-variable=LockToLockEna.Logl
          sync call SC_GetRefTmr1MicroSec32bit_PortIf1_Oper: operation=GetRefTmr1MicroSec32bit.Oper, timeout=0
          sync call SC_GetTiSpan1MicroSec32bit_PortIf1_Oper: operation=GetTiSpan1MicroSec32bit.Oper, timeout=0
          sync call SC_MilesKmEeprom_SetRamBlockStatus: operation=MilesKmEeprom.SetRamBlockStatus, timeout=0
        BmwDiagcSrvHndlgStatusFzgBordnetzRead_Oper
        BmwDiagcSrvHndlgStatusFzgBordnetzReadCdnChk_Oper
      4 x swc service dependency:
        NvmMilesKmEeprom: assigned-datas=role-based-data-assignment={role=ramBlock, used-data-element=MilesKmEeprom}, assigned-ports=role-based-port-assignment={port-prototype=MilesKmEeprom, role=NvMService_AC3_SRBS}
          service-needs:
            nv block needs NvmMilesKmEeprom: n-data-sets=0, ram-block-status-control=API, readonly=false, reliability=NO-PROTECTION, resistant-to-changed-sw=true, restore-at-start=true, store-at-shutdown=true, write-only-once=false, writing-frequency=0, writing-priority=LOW
        NvmProgCntr: assigned-datas=role-based-data-assignment={role=ramBlock, used-data-element=ProgCntr}, assigned-ports=role-based-port-assignment={port-prototype=ProgCntr, role=NvMService_AC3_SRBS}
          service-needs:
            nv block needs NvmProgCntr: n-data-sets=0, ram-block-status-control=API, readonly=true, reliability=NO-PROTECTION, restore-at-start=true, store-at-shutdown=false, write-only-once=false
        NvmProgCntrMaxVal: assigned-ports=role-based-port-assignment={port-prototype=ProgCntrMaxVal, role=NvMService_AC3_SRBS}
          assigned-datas:
            role=ramBlock, used-data-element=ProgCntrMaxVal
            role=defaultValue, used-parameter-element=ProgCntrMaxValDft
          service-needs:
            nv block needs NvmProgCntrMaxVal: n-data-sets=0, ram-block-status-control=API, reliability=NO-PROTECTION, resistant-to-changed-sw=true, restore-at-start=true, store-at-shutdown=true, write-only-once=false, writing-frequency=0, writing-priority=LOW
        NvmTestStamp: assigned-datas=role-based-data-assignment={role=ramBlock, used-data-element=TestStamp}, assigned-ports=role-based-port-assignment={port-prototype=TestStamp, role=NvMService_AC3_SRBS}
          service-needs:
            nv block needs NvmTestStamp: n-data-sets=0, ram-block-status-control=API, readonly=false, reliability=NO-PROTECTION, resistant-to-changed-sw=true, restore-at-start=true, store-at-shutdown=true, write-only-once=false, writing-frequency=0, writing-priority=LOW
      shared-parameters:
        parameter data prototype NvmProgCntr_DefaultValue: sw-calibration-access=READ-ONLY, type=uint16, init-value=0
  swc implementation BmwDiagcSrvHndlg_Implementation: behavior=BmwDiagcSrvHndlg_InternalBehavior
    code-descriptors:
      code Default: artifact-descriptors=autosar-engineering-object={short-label=Default, category=SWSRC}
